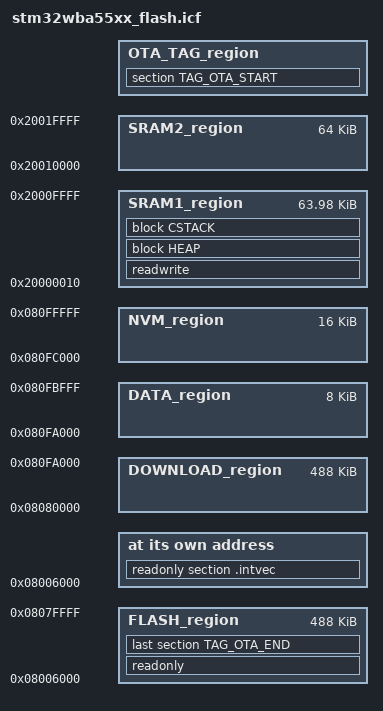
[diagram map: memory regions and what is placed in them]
/**********************************************************************************/
/**** Linker File (ICF)                                                        ****/
/**********************************************************************************/

/*-Symbols-*/

define symbol __region_NVM_size__          = 0x4000;
define symbol __region_NVM_end__           = 0x080FFFFF;
define symbol __region_NVM_start__         = __region_NVM_end__ - __region_NVM_size__ + 0x1;

define symbol __region_DATA_size__         = 0x2000;
define symbol __region_DATA_end__          = __region_NVM_start__ - 0x1;
define symbol __region_DATA_start__        = __region_DATA_end__ - __region_DATA_size__ + 0x1;

define symbol __region_DOWNLOAD_start__    = 0x08080000;
define symbol __region_DOWNLOAD_end__      = 0x080FA000;

define symbol __region_FLASH_start__       = 0x08006000;
define symbol __region_FLASH_end__         = 0x0807FFFF;

define symbol __region_SRAM1_start__       = 0x20000010;
define symbol __region_SRAM1_end__         = 0x2000FFFF;
define symbol __region_SRAM2_start__       = 0x20010000;
define symbol __region_SRAM2_end__         = 0x2001FFFF;

define symbol __size_heap__                = 0x3000;
define symbol __size_cstack__              = 0x1000;
define symbol __intvec_start__             = __region_FLASH_start__;
define symbol __intvec_end__               = (__intvec_start__ + 0x160);

/*-Memory Regions-*/
define memory mem with size = 4G;
define region NVM_region      = mem:[from __region_NVM_start__ to __region_NVM_end__];
define region DATA_region     = mem:[from __region_DATA_start__ to __region_DATA_end__];
define region DOWNLOAD_region = mem:[from __region_DOWNLOAD_start__ to __region_DOWNLOAD_end__];
define region FLASH_region    = mem:[from __region_FLASH_start__ to __region_FLASH_end__];
define region SRAM1_region    = mem:[from __region_SRAM1_start__ to __region_SRAM1_end__];
define region SRAM2_region    = mem:[from __region_SRAM2_start__ to __region_SRAM2_end__];
define region SRAM_region     = SRAM1_region | SRAM2_region;
define region OTA_TAG_region  = mem:[from __intvec_end__ to (__intvec_end__ + 4)];

/*-Blocks-*/
define block HEAP      with alignment = 8, size = __size_heap__   { };
define block CSTACK    with alignment = 8, size = __size_cstack__ { };

/*-Initialization strategies-*/
initialize by copy { readwrite };
do not initialize  { section .noinit };

/*-Sections placements-*/
place at address mem:__intvec_start__ { readonly section .intvec };

place in NVM_region         { };
place in DATA_region        { };
place in DOWNLOAD_region    { };
keep                        { section TAG_OTA_START};
keep                        { section TAG_OTA_END };
place in OTA_TAG_region     { section TAG_OTA_START };
place in FLASH_region       { readonly, last section TAG_OTA_END  };

place in SRAM1_region       { readwrite, block HEAP, block CSTACK };
place in SRAM2_region       { };
place in SRAM_region        { };
